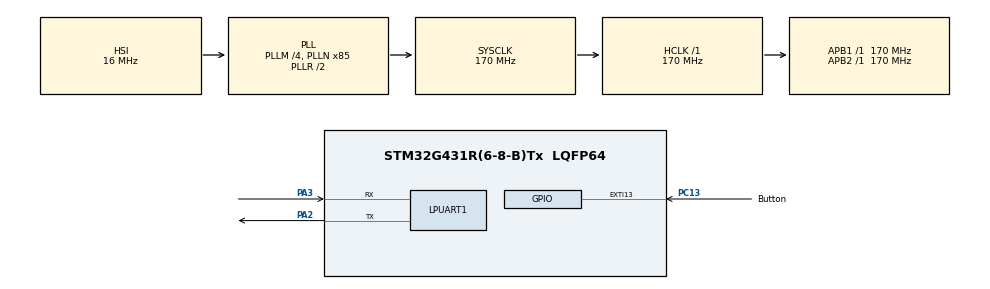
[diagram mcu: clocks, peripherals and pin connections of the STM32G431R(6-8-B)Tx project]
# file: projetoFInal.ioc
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FREERTOS.Tasks01=defaultTask,0,128,StartDefaultTask,Default,NULL,Dynamic,NULL,NULL
FREERTOS.configENABLE_FPU=1
FREERTOS.configUSE_NEWLIB_REENTRANT=1
Mcu.Family=STM32G4
Mcu.Name=STM32G431R(6-8-B)Tx
Mcu.Package=LQFP64
NVIC.EXTI15_10_IRQn=true\:5\:0\:false\:false\:true\:true\:true\:true\:true
NVIC.PriorityGroup=NVIC_PRIORITYGROUP_4
NVIC.TIM1_UP_TIM16_IRQn=true\:15\:0\:false\:false\:true\:false\:false\:true\:true
NVIC.TimeBase=TIM1_UP_TIM16_IRQn
NVIC.TimeBaseIP=TIM1
PA13.Mode=Serial_Wire
PA13.Signal=SYS_JTMS-SWDIO
PA14.Mode=Serial_Wire
PA14.Signal=SYS_JTCK-SWCLK
PA2.Mode=Asynchronous
PA2.Signal=LPUART1_TX
PA3.Mode=Asynchronous
PA3.Signal=LPUART1_RX
PC13.GPIO_Label=Button
PC13.GPIO_PuPd=GPIO_PULLDOWN
PC13.Signal=GPXTI13
PF0-OSC_IN.Mode=HSE-External-Oscillator
PF0-OSC_IN.Signal=RCC_OSC_IN
PF1-OSC_OUT.Mode=HSE-External-Oscillator
PF1-OSC_OUT.Signal=RCC_OSC_OUT
ProjectManager.HeapSize=0x200
ProjectManager.StackSize=0x400
ProjectManager.TargetToolchain=STM32CubeIDE
RCC.ADC12Freq_Value=170000000
RCC.AHBFreq_Value=170000000
RCC.APB1Freq_Value=170000000
RCC.APB1TimFreq_Value=170000000
RCC.APB2Freq_Value=170000000
RCC.APB2TimFreq_Value=170000000
RCC.CortexFreq_Value=170000000
RCC.EXTERNAL_CLOCK_VALUE=12288000
RCC.HCLKFreq_Value=170000000
RCC.HSE_VALUE=48000000
RCC.HSI48_VALUE=48000000
RCC.HSI_VALUE=16000000
RCC.LSE_VALUE=32768
RCC.PLLM=RCC_PLLM_DIV4
RCC.PLLN=85
RCC.SYSCLKFreq_VALUE=170000000
RCC.SYSCLKSource=RCC_SYSCLKSOURCE_PLLCLK
RCC.USBFreq_Value=170000000
RCC.VCOOutputFreq_Value=340000000
VP_FREERTOS_VS_CMSIS_V1.Mode=CMSIS_V1
VP_SYS_VS_DBSignals.Mode=DisableDeadBatterySignals
VP_SYS_VS_tim1.Mode=TIM1
board=custom

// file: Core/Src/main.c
/* USER CODE BEGIN Header */
/**
  ******************************************************************************
  * @file           : main.c
  * @brief          : Main program body
  ******************************************************************************
  * @attention
  *
  * Copyright (c) 2025 STMicroelectronics.
  * All rights reserved.
  *
  * This software is licensed under terms that can be found in the LICENSE file
  * in the root directory of this software component.
  * If no LICENSE file comes with this software, it is provided AS-IS.
  *
  ******************************************************************************
  */
/* USER CODE END Header */
#include "main.h"
#include "cmsis_os.h"

UART_HandleTypeDef hlpuart1;

osThreadId defaultTaskHandle;
/* USER CODE BEGIN PV */
SemaphoreHandle_t bSemaphore;
/* USER CODE END PV */

void SystemClock_Config(void);
static void MX_GPIO_Init(void);
static void MX_LPUART1_UART_Init(void);
void StartDefaultTask(void const * argument);

/* USER CODE BEGIN 0 */
typedef struct leds_t_ {
	GPIO_TypeDef* port;
	uint16_t pin;
	TickType_t time;
}led_t;

void led_task(void *args){
	led_t *led = (led_t *) args;

	while(1){
		HAL_GPIO_TogglePin(led->port, led->pin);
	}
}

void button_task(){

	while(1){
		xSemaphoreTake(bSemaphore,portMAX_DELAY);
		vTaskDelay(50);
		HAL_NVIC_EnableIRQ(EXTI15_10_IRQn);
	}
}
/* USER CODE END 0 */

int main(void)
{

  /* USER CODE BEGIN 1 */
	static led_t led = {.port = GPIOA, .pin = GPIO_PIN_5, .time = 500};
	(void)xTaskCreate(led_task, "led_task", 256, &led, 7, NULL);
	(void)xTaskCreate(button_task, "button_task", 256, NULL, 7, NULL);
  /* USER CODE END 1 */

  /* MCU Configuration--------------------------------------------------------*/

  /* Reset of all peripherals, Initializes the Flash interface and the Systick. */
  HAL_Init();

  /* Configure the system clock */
  SystemClock_Config();

  /* Initialize all configured peripherals */
  MX_GPIO_Init();
  MX_LPUART1_UART_Init();
  /* USER CODE BEGIN 2 */
  void TransmitUartFreeRTOS(uint8_t *data, uint32_t len, TickType_t timeout){

  }
  /* USER CODE END 2 */

  /* USER CODE BEGIN RTOS_SEMAPHORES */
  /* add semaphores, ... */
  bSemaphore = xSemaphoreCreateBinary();
  /* USER CODE END RTOS_SEMAPHORES */

  /* Create the thread(s) */
  /* definition and creation of defaultTask */
  osThreadDef(defaultTask, StartDefaultTask, osPriorityNormal, 0, 128);
  defaultTaskHandle = osThreadCreate(osThread(defaultTask), NULL);

  /* Start scheduler */
  osKernelStart();

  /* We should never get here as control is now taken by the scheduler */

  /* Infinite loop */
  while (1)
  {

  }
}

void SystemClock_Config(void)
{
  RCC_OscInitTypeDef RCC_OscInitStruct = {0};
  RCC_ClkInitTypeDef RCC_ClkInitStruct = {0};

  /** Configure the main internal regulator output voltage
  */
  HAL_PWREx_ControlVoltageScaling(PWR_REGULATOR_VOLTAGE_SCALE1_BOOST);

  /** Initializes the RCC Oscillators according to the specified parameters
  * in the RCC_OscInitTypeDef structure.
  */
  RCC_OscInitStruct.OscillatorType = RCC_OSCILLATORTYPE_HSI;
  RCC_OscInitStruct.HSIState = RCC_HSI_ON;
  RCC_OscInitStruct.HSICalibrationValue = RCC_HSICALIBRATION_DEFAULT;
  RCC_OscInitStruct.PLL.PLLState = RCC_PLL_ON;
  RCC_OscInitStruct.PLL.PLLSource = RCC_PLLSOURCE_HSI;
  RCC_OscInitStruct.PLL.PLLM = RCC_PLLM_DIV4;
  RCC_OscInitStruct.PLL.PLLN = 85;
  RCC_OscInitStruct.PLL.PLLP = RCC_PLLP_DIV2;
  RCC_OscInitStruct.PLL.PLLQ = RCC_PLLQ_DIV2;
  RCC_OscInitStruct.PLL.PLLR = RCC_PLLR_DIV2;
  if (HAL_RCC_OscConfig(&RCC_OscInitStruct) != HAL_OK)
  {
    Error_Handler();
  }

  /** Initializes the CPU, AHB and APB buses clocks
  */
  RCC_ClkInitStruct.ClockType = RCC_CLOCKTYPE_HCLK|RCC_CLOCKTYPE_SYSCLK
                              |RCC_CLOCKTYPE_PCLK1|RCC_CLOCKTYPE_PCLK2;
  RCC_ClkInitStruct.SYSCLKSource = RCC_SYSCLKSOURCE_PLLCLK;
  RCC_ClkInitStruct.AHBCLKDivider = RCC_SYSCLK_DIV1;
  RCC_ClkInitStruct.APB1CLKDivider = RCC_HCLK_DIV1;
  RCC_ClkInitStruct.APB2CLKDivider = RCC_HCLK_DIV1;

  if (HAL_RCC_ClockConfig(&RCC_ClkInitStruct, FLASH_LATENCY_4) != HAL_OK)
  {
    Error_Handler();
  }
}

static void MX_LPUART1_UART_Init(void)
{

  hlpuart1.Instance = LPUART1;
  hlpuart1.Init.BaudRate = 209700;
  hlpuart1.Init.WordLength = UART_WORDLENGTH_8B;
  hlpuart1.Init.StopBits = UART_STOPBITS_1;
  hlpuart1.Init.Parity = UART_PARITY_NONE;
  hlpuart1.Init.Mode = UART_MODE_TX_RX;
  hlpuart1.Init.HwFlowCtl = UART_HWCONTROL_NONE;
  hlpuart1.Init.OneBitSampling = UART_ONE_BIT_SAMPLE_DISABLE;
  hlpuart1.Init.ClockPrescaler = UART_PRESCALER_DIV1;
  hlpuart1.AdvancedInit.AdvFeatureInit = UART_ADVFEATURE_NO_INIT;
  if (HAL_UART_Init(&hlpuart1) != HAL_OK)
  {
    Error_Handler();
  }
  if (HAL_UARTEx_SetTxFifoThreshold(&hlpuart1, UART_TXFIFO_THRESHOLD_1_8) != HAL_OK)
  {
    Error_Handler();
  }
  if (HAL_UARTEx_SetRxFifoThreshold(&hlpuart1, UART_RXFIFO_THRESHOLD_1_8) != HAL_OK)
  {
    Error_Handler();
  }
  if (HAL_UARTEx_DisableFifoMode(&hlpuart1) != HAL_OK)
  {
    Error_Handler();
  }

}

static void MX_GPIO_Init(void)
{
  GPIO_InitTypeDef GPIO_InitStruct = {0};

  /* GPIO Ports Clock Enable */
  __HAL_RCC_GPIOC_CLK_ENABLE();
  __HAL_RCC_GPIOF_CLK_ENABLE();
  __HAL_RCC_GPIOA_CLK_ENABLE();

  /*Configure GPIO pin : Button_Pin */
  GPIO_InitStruct.Pin = Button_Pin;
  GPIO_InitStruct.Mode = GPIO_MODE_IT_RISING;
  GPIO_InitStruct.Pull = GPIO_PULLDOWN;
  HAL_GPIO_Init(Button_GPIO_Port, &GPIO_InitStruct);

  /* EXTI interrupt init*/
  HAL_NVIC_SetPriority(EXTI15_10_IRQn, 5, 0);
  HAL_NVIC_EnableIRQ(EXTI15_10_IRQn);

}

/* USER CODE BEGIN 4 */
void HAL_GPIO_EXITI_Callback(uint16_t GPIO_Pin)
{
	BaseType_t xHigherPriorityTaskWoken = pdFALSE;
	if (GPIO_Pin == Button_Pin)
	{
		HAL_NVIC_DisableIRQ(EXTI15_10_IRQn);
		xSemaphoreGiveFromISR(bSemaphore, &xHigherPriorityTaskWoken);
		portYIELD_FROM_ISR(xHigherPriorityTaskWoken);
	}
}
/* USER CODE END 4 */

void StartDefaultTask(void const * argument)
{
  for(;;)
  {
    osDelay(1);
  }
}

void HAL_TIM_PeriodElapsedCallback(TIM_HandleTypeDef *htim)
{
  if (htim->Instance == TIM1)
  {
    HAL_IncTick();
  }
}

void Error_Handler(void)
{
  __disable_irq();
  while (1)
  {
  }
}
